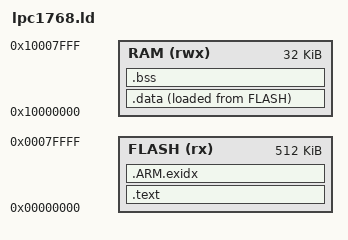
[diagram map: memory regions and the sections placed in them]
ENTRY(Reset_Handler)
MEMORY { FLASH (rx) : ORIGIN = 0x00000000, LENGTH = 512K
         RAM (rwx) : ORIGIN = 0x10000000, LENGTH = 32K }
SECTIONS {
 .text : { KEEP(*(.vectors)) *(.text*) *(.rodata*) } > FLASH
 .ARM.exidx : { *(.ARM.exidx*) } > FLASH
 .data : { . = ALIGN(4); _sdata = .; *(.data*) . = ALIGN(4); _edata = .; } > RAM AT> FLASH
 _sidata = LOADADDR(.data);
 .bss (NOLOAD) : { . = ALIGN(4); _sbss = .; *(.bss*) *(COMMON) . = ALIGN(4); _ebss = .; _end = .; } > RAM
 ASSERT(_end < 0x10006000, "Data leaves insufficient space for heap and stack")
}
